# CH583SFR register map
Vendor: WCH Ltd.; Series: CH58x; File version: 1.0
CPU: RISC-V r0p0, little endian, no MPU, no FPU, 2 interrupt priority bits
Registers are 8-bit, read-write, reset 0x0 unless marked. A register's access mark holds for its fields unless they carry their own. Offsets are from the block's base; [hi:lo] are bit positions; {n}, {i} and the like mark numbered series.

## SYS — System Control Register
Base 0x40001000
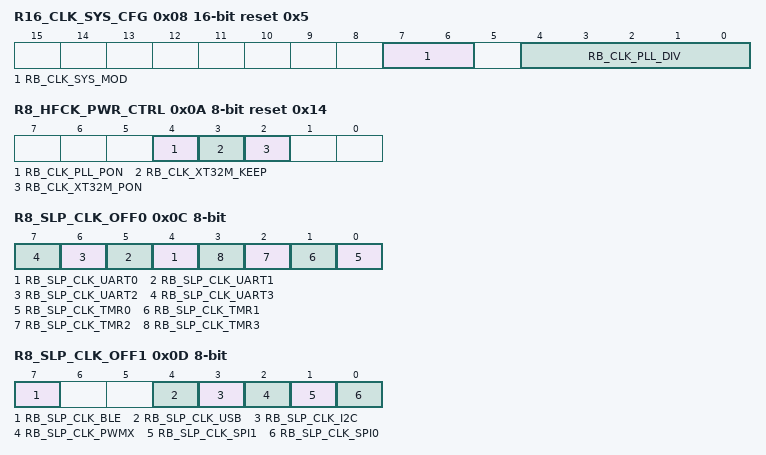
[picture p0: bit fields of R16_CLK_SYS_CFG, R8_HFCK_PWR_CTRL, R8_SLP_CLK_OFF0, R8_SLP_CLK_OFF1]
0x08 R16_CLK_SYS_CFG 16-bit reset 0x5 — RWA, system clock configuration, SAM
  [7:6] RB_CLK_SYS_MOD — RWA, system clock source mode: 00=divided from 32MHz, 01=divided from PLL-480MHz, 10=directly from 32MHz, 11=directly from 32KHz
  [4:0] RB_CLK_PLL_DIV — RWA, output clock divider from PLL or CK32M
0x0A R8_HFCK_PWR_CTRL reset 0x14 — RWA, high frequency clock module power control, SAM
  [4] RB_CLK_PLL_PON — RWA, PLL power control: 0=power down, 1-power on
  [3] RB_CLK_XT32M_KEEP — RWA, external 32MHz oscillator power keep under halt mode: 0=auto stop, 1=keep running
  [2] RB_CLK_XT32M_PON — RWA, external 32MHz oscillator power control: 0=power down, 1-power on
0x0C R8_SLP_CLK_OFF0 Read or  Write under safe Accessing mode — RWA, sleep clock off control byte 0, SAM
  [n+4] RB_SLP_CLK_UART{n} (n=0..3) — RWA, close UART{n} clock
  [n] RB_SLP_CLK_TMR{n} (n=0..3) — RWA, close TMR{n} clock
0x0D R8_SLP_CLK_OFF1 Read or  Write under safe Accessing mode — RWA, sleep clock off control byte 1, SAM
  [7] RB_SLP_CLK_BLE — RWA, close BLE clock
  [4] RB_SLP_CLK_USB — RWA, close USB clock
  [3] RB_SLP_CLK_I2C — RWA, close I2C clock
  [2] RB_SLP_CLK_PWMX — RWA, close PWMx clock
  [1] RB_SLP_CLK_SPI1 — RWA, close SPI1 clock
  [0] RB_SLP_CLK_SPI0 — RWA, close SPI0 clock
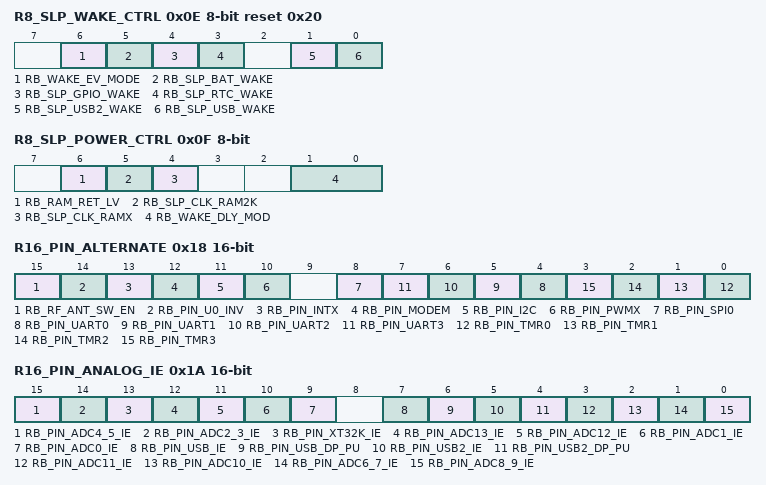
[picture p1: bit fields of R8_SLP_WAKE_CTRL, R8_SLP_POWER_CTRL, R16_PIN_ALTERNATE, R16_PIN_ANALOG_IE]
0x0E R8_SLP_WAKE_CTRL Read or Write under safe Accessing mode reset 0x20 — RWA, wake control, SAM
  [6] RB_WAKE_EV_MODE — RWA, event wakeup mode
  [5] RB_SLP_BAT_WAKE — RWA, enable BAT waking
  [4] RB_SLP_GPIO_WAKE — RWA, enable GPIO waking
  [3] RB_SLP_RTC_WAKE — RWA, enable RTC waking
  [1] RB_SLP_USB2_WAKE — RWA, enable USB2 waking
  [0] RB_SLP_USB_WAKE — RWA, enable USB waking
0x0F R8_SLP_POWER_CTRL Read or Write under safe Accessing mode — RWA, peripherals power down control, SAM
  [6] RB_RAM_RET_LV — RWA, SRAM retention voltage selection
  [5] RB_SLP_CLK_RAM2K — RWA, close retention 2KB SRAM clock
  [4] RB_SLP_CLK_RAMX — RWA, close main SRAM clock
  [1:0] RB_WAKE_DLY_MOD — RWA, wakeup delay time selection
0x18 R16_PIN_ALTERNATE 16-bit — RW, function pin alternate configuration
  [15] RB_RF_ANT_SW_EN — RW, RF antenna switch control output enable
  [14] RB_PIN_U0_INV — RW, SCL/SDA alternRW, RXD0/RXD0_/TXD0/TXD0_ invert input/output enableate pin enable
  [13] RB_PIN_INTX — RW, interrupt INT24/INT25 alternate pin enable
  [12] RB_PIN_MODEM — RW, DSR/DTR alternate pin enable
  [11] RB_PIN_I2C — RW, SCL/SDA alternate pin enable
  [10] RB_PIN_PWMX — RW, PWM4/PWM5/PWM7/PWM8/PWM9 alternate pin enable
  [8] RB_PIN_SPI0 — RW, SCS/SCK0/MOSI/MISO alternate pin enable
  [n+4] RB_PIN_UART{n} (n=0..3) — RW, RXD{n}/TXD{n} alternate pin enable
  [n] RB_PIN_TMR{n} (n=0..3) — RW, TMR{n} alternate pin enable
0x1A R16_PIN_ANALOG_IE 16-bit — RW, analog pin enable and digital input disable
  [15] RB_PIN_ADC4_5_IE — RW, ADC/TouchKey channel 4/5 digital input disable: 0=digital input enable, 1=digital input disable
  [14] RB_PIN_ADC2_3_IE — RW, ADC/TouchKey channel 2/3 digital input disable: 0=digital input enable, 1=digital input disable
  [13] RB_PIN_XT32K_IE — RW, external 32KHz oscillator digital input disable: 0=digital input enable, 1=digital input disable
  [12] RB_PIN_ADC13_IE — RW, ADC/TouchKey channel13 digital input disable: 0=digital input enable, 1=digital input disable
  [11] RB_PIN_ADC12_IE — RW, ADC/TouchKey channel12 digital input disable: 0=digital input enable, 1=digital input disable
  [10] RB_PIN_ADC1_IE — RW, ADC/TouchKey channel1 digital input disable: 0=digital input enable, 1=digital input disable
  [9] RB_PIN_ADC0_IE — RW, ADC/TouchKey channel0 digital input disable: 0=digital input enable, 1=digital input disable
  [7] RB_PIN_USB_IE — RW, USB analog I/O enable: 0=analog I/O disable, 1=analog I/O enable
  [6] RB_PIN_USB_DP_PU — RW,USB UDP internal pullup resistance enable
  [5] RB_PIN_USB2_IE — RW, USB analog I/O enable: 0=analog I/O disable, 1=analog I/O enable
  [4] RB_PIN_USB2_DP_PU — RW,USB2 UDP internal pullup resistance enable
  [3] RB_PIN_ADC11_IE — RW, ADC/TouchKey channel 11 digital input disable
  [2] RB_PIN_ADC10_IE — RW, ADC/TouchKey channel 10 digital input disable
  [1] RB_PIN_ADC6_7_IE — RW, ADC/TouchKey channel 7/6 digital input disable
  [0] RB_PIN_ADC8_9_IE — RW, ADC/TouchKey channel 9/8 digital input disable
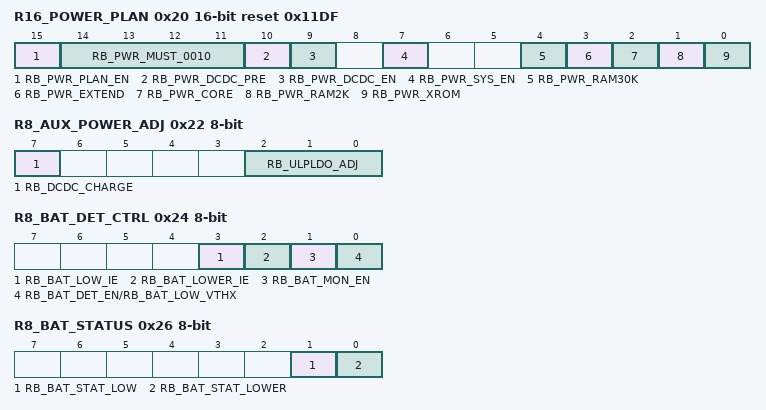
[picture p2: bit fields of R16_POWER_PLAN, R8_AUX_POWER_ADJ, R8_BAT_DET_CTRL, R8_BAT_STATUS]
0x20 R16_POWER_PLAN 16-bit Read or Write under safe Accessing mode reset 0x11DF — RWA, power plan before sleep instruction, SAM
  [15] RB_PWR_PLAN_EN ro — RWA, must write 0010
  [14:11] RB_PWR_MUST_0010 ro — RWA, power plan enable, auto clear after sleep executed
  [10] RB_PWR_DCDC_PRE — RWA, DC/DC converter pre-enable
  [9] RB_PWR_DCDC_EN — RWA, DC/DC converter enable: 0=DC/DC disable and bypass, 1=DC/DC enable
  [7] RB_PWR_SYS_EN — RWA, power for system
  [4] RB_PWR_RAM30K — RWA, power for main SRAM
  [3] RB_PWR_EXTEND — RWA, power retention for USB and BLE
  [2] RB_PWR_CORE — RWA, power retention for core and base peripherals
  [1] RB_PWR_RAM2K — RWA, power for retention 2KB SRAM
  [0] RB_PWR_XROM — RWA, power for retention 2KB SRAM
0x22 R8_AUX_POWER_ADJ Read or Write under safe Accessing mode — RWA, aux power adjust control, SAM
  [7] RB_DCDC_CHARGE rw — RWA, Ultra-Low-Power LDO voltage adjust
  [2:0] RB_ULPLDO_ADJ rw — RWA, Ultra-Low-Power LDO voltage adjust
0x24 R8_BAT_DET_CTRL Read / Write under safe Accessing mode — RWA, battery voltage detector control, SAM
  [3] RB_BAT_LOW_IE — RWA, interrupt enable for battery low voltage
  [2] RB_BAT_LOWER_IE — RWA, interrupt enable for battery lower voltage
  [1] RB_BAT_MON_EN — RWA, battery voltage monitor enable under sleep mode
  [0] RB_BAT_DET_EN/RB_BAT_LOW_VTHX — RWA, battery voltage detector enable/select monitor threshold voltage
0x25 R8_BAT_DET_CFG Read or Write under safe Accessing mode reset 0x1 — RWA, battery voltage detector configuration, SAM
  [1:0] RB_BAT_LOW_VTH — RWA, select threshold voltage of battery voltage low
0x26 R8_BAT_STATUS ro — RO, battery status
  [1] RB_BAT_STAT_LOW — RO, battery low voltage status, high action
  [0] RB_BAT_STAT_LOWER — RO, battery lower voltage status, high action
0x2C R16_INT32K_TUNE 16-bit Read or Write under safe Accessing mode reset 0x1011 — RWA, internal 32KHz oscillator tune control, SAM
  [12:0] RB_INT32K_TUNE — RWA, internal 32KHz oscillator frequency tune
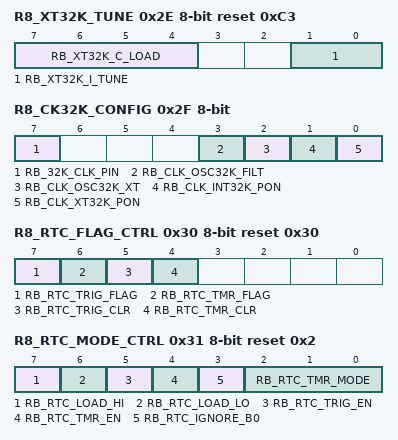
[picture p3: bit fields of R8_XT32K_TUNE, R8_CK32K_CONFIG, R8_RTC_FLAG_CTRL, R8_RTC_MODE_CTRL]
0x2E R8_XT32K_TUNE Read or Write under safe Accessing mode reset 0xC3 — RWA, external 32KHz oscillator tune control, SAM
  [7:4] RB_XT32K_C_LOAD — RWA, external 32KHz oscillator load capacitor tune: Cap = RB_XT32K_C_LOAD + 12pF
  [1:0] RB_XT32K_I_TUNE — RWA, external 32KHz oscillator current tune: 00=75% current, 01=standard current, 10=150% current, 11=200% current
0x2F R8_CK32K_CONFIG Read or  Write under safe Accessing mode reset not defined — RWA, 32KHz oscillator configure
  [7] RB_32K_CLK_PIN ro — RO, 32KHz oscillator clock pin status
  [3] RB_CLK_OSC32K_FILT rw — RWA, internal 32KHz oscillator low noise mode enable
  [2] RB_CLK_OSC32K_XT rw — RWA, 32KHz oscillator source selection: 0=RC, 1=XT
  [1] RB_CLK_INT32K_PON rw — RWA, internal 32KHz oscillator power on
  [0] RB_CLK_XT32K_PON rw — RWA, external 32KHz oscillator power on
0x30 R8_RTC_FLAG_CTRL reset 0x30 — RW, RTC flag and clear control
  [7] RB_RTC_TRIG_FLAG ro — RO, RTC trigger action flag
  [6] RB_RTC_TMR_FLAG ro — RO, RTC timer action flag
  [5] RB_RTC_TRIG_CLR — RW, set 1 to clear RTC trigger action flag, auto clear
  [4] RB_RTC_TMR_CLR — RW, set 1 to clear RTC timer action flag, auto clear
0x31 R8_RTC_MODE_CTRL Read or Write under safe Accessing mode reset 0x2 — RWA, RTC mode control, SAM
  [7] RB_RTC_LOAD_HI — RWA, set 1 to load RTC count high word R32_RTC_CNT_DAY, auto clear after loaded
  [6] RB_RTC_LOAD_LO — RWA, set 1 to load RTC count low word R32_RTC_CNT_32K, auto clear after loaded
  [5] RB_RTC_TRIG_EN — RWA, RTC trigger mode enable
  [4] RB_RTC_TMR_EN — RWA, RTC timer mode enable
  [3] RB_RTC_IGNORE_B0 — RWA, force ignore bit0 for trigger mode: 0=compare bit0, 1=ignore bit0
  [2:0] RB_RTC_TMR_MODE — RWA, RTC timer mode: 000=0.125S, 001=0.25S, 010=0.5S, 011=1S, 100=2S, 101=4S, 110=8S, 111=16S
0x34 R32_RTC_TRIG 32-bit Read or Write under safe Accessing mode — RWA, RTC trigger value, SAM
  [31:0] R32_RTC_TRIG — RWA, RTC trigger value
0x38 R16_RTC_CNT_32K 16-bit ro — RO, RTC count based 32KHz
  [15:0] R16_RTC_CNT_32K — RWA,RTC count based 32KHz
0x3A R16_RTC_CNT_2S 16-bit ro — RO, RTC count based 2 second
0x3C R32_RTC_CNT_DAY 32-bit ro — RO, RTC count based one day, only low 14 bit
  [13:0] R32_RTC_CNT_DAY — RWA,RTC count based one day
0x40 R8_SAFE_ACCESS_SIG read/write — WO, safe accessing sign register, must write SAFE_ACCESS_SIG1 then SAFE_ACCESS_SIG2 to enter safe accessing mode
  [6:4] RB_SAFE_ACC_TIMER — RO, safe accessing timer bit mask (16*clock number)
  [3] RB_SAFE_ACC_ACT — RO, indicate safe accessing status now: 0=locked, read only, 1=safe/unlocked (SAM), write enabled
  [1:0] RB_SAFE_ACC_MODE — RO, current safe accessing mode: 11=safe unlocked (SAM), other=locked (00..01..10..11)
  [7:0] R8_SAFE_ACCESS_SIG — WO, safe accessing sign register, must write 0x57 then 0xA8 to enter safe accessing mode
0x41 R8_CHIP_ID -Read only for Fixed value reset 0x83 — RF, chip ID register, always is ID_CH58*
  [7:0] R8_CHIP_ID — RF,chip ID register
0x42 R8_SAFE_ACCESS_ID -Read only for Fixed value reset 0xC — RF, safe accessing ID register, always 0x0C
  [7:0] R8_SAFE_ACCESS_ID — RF,safe accessing ID register
0x43 R8_WDOG_COUNT — RW, watch-dog count, count by clock frequency Fsys/131072
  [7:0] R8_WDOG_COUNT — RF,watch-dog count, count by clock frequency Fsys/131072
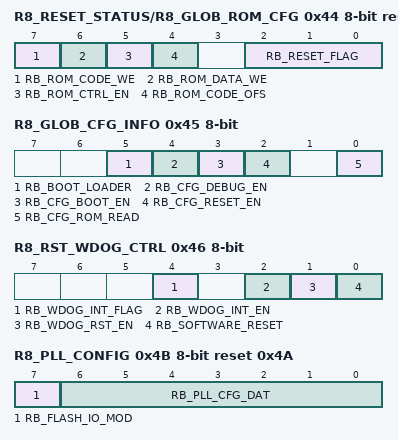
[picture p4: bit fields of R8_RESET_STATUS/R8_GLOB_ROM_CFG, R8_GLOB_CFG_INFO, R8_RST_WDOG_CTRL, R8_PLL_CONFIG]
0x44 R8_RESET_STATUS/R8_GLOB_ROM_CFG -Read only for Fixed value reset 0x1 — RWA, reset status, SAM or flash ROM configuration
  [7] RB_ROM_CODE_WE rw — RWA, enable flash ROM code area being erase or write
  [6] RB_ROM_DATA_WE rw — RWA,enable flash ROM data and code area being erase/write
  [5] RB_ROM_CTRL_EN rw — RWA, enable flash ROM control interface enable
  [4] RB_ROM_CODE_OFS rw — RWA, code offset address selection in Flash ROM: 0=start address 0x000000, 1=start address 0x008000
  [2:0] RB_RESET_FLAG ro — RO, recent reset flag
0x45 R8_GLOB_CFG_INFO ro reset not defined — RO, global configuration information and status
  [5] RB_BOOT_LOADER — RO, indicate boot loader status: 0=application status (by software reset), 1=boot loader status
  [4] RB_CFG_DEBUG_EN — RO, debug enable status
  [3] RB_CFG_BOOT_EN — RO, boot-loader enable status
  [2] RB_CFG_RESET_EN — RO, manual reset input enable status
  [0] RB_CFG_ROM_READ — RO, indicate protected status of Flash ROM code and data: 0=reading protect, 1=enable read by external programmer
0x46 R8_RST_WDOG_CTRL Read or Write under safe Accessing mode — RWA, reset and watch-dog control, SAM
  [4] RB_WDOG_INT_FLAG — RW1, watch-dog timer overflow interrupt flag, cleared by RW1 or reload watch-dog count or __SEV(Send-Event)
  [2] RB_WDOG_INT_EN — RWA, watch-dog timer overflow interrupt enable: 0=disable, 1=enable
  [1] RB_WDOG_RST_EN — RWA, enable watch-dog reset if watch-dog timer overflow: 0=as timer only, 1=enable reset if timer overflow
  [0] RB_SOFTWARE_RESET — WA or WZ, global software reset, high action, auto clear
0x47 R8_GLOB_RESET_KEEP — RW, value keeper during global reset
0x4B R8_PLL_CONFIG Read or Write under safe Accessing mode reset 0x4A — RWA, PLL configuration control, SAM
  [7] RB_FLASH_IO_MOD rw — RWA, flash ROM interface mode
  [6:0] RB_PLL_CFG_DAT rw — RWA, PLL configure data
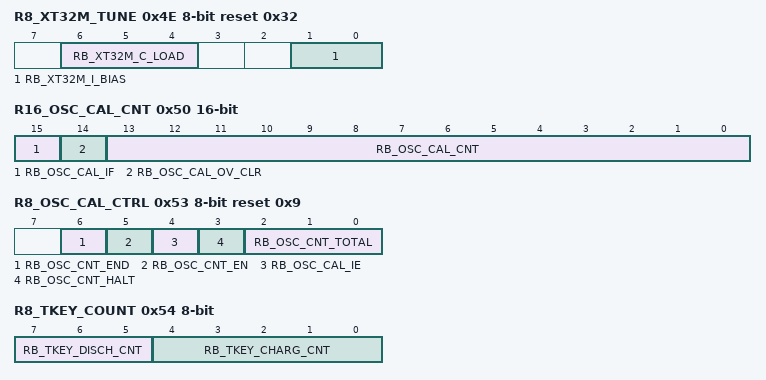
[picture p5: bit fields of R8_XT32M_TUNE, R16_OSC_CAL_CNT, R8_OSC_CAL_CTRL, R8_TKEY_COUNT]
0x4E R8_XT32M_TUNE Read or Write under safe Accessing mode reset 0x32 — RWA, external 32MHz oscillator tune control, SAM
  [6:4] RB_XT32M_C_LOAD rw — RWA, external 32MHz oscillator load capacitor tune: Cap = RB_XT32M_C_LOAD * 2 + 10pF
  [1:0] RB_XT32M_I_BIAS rw — RWA, external 32MHz oscillator bias current tune: 00=75% current, 01=standard current, 10=125% current, 11=150% current
0x50 R16_OSC_CAL_CNT 16-bit ro — RO, system clock count value for 32KHz multi-cycles
  [15] RB_OSC_CAL_IF — RW1, interrupt flag for oscillator capture end, set 1 to clear
  [14] RB_OSC_CAL_OV_CLR — RW1, indicate R8_OSC_CAL_OV_CNT not zero, set 1 to clear R8_OSC_CAL_OV_CNT
  [13:0] RB_OSC_CAL_CNT — RO, system clock count value for 32KHz multi-cycles
0x52 R8_OSC_CAL_OV_CNT Read Only — RO, oscillator frequency calibration overflow times
  [7:0] R8_OSC_CAL_OV_CNT read only
0x53 R8_OSC_CAL_CTRL Read or Write under safe Accessing mode reset 0x9 — RWA, oscillator frequency calibration control, SAM
  [6] RB_OSC_CNT_END rw — RWA, select oscillator capture end mode: 0=normal, 1=append 2 cycles
  [5] RB_OSC_CNT_EN rw — RWA, calibration counter enable
  [4] RB_OSC_CAL_IE rw — RWA, interrupt enable for oscillator capture end
  [3] RB_OSC_CNT_HALT ro — RO, calibration counter halt status: 0=counting, 1=halt for reading count value
  [2:0] RB_OSC_CNT_TOTAL rw — RWA, total cycles mode for oscillator capture
0x54 R8_TKEY_COUNT — RW, Touchkey charge and discharge count
  [7:5] RB_TKEY_DISCH_CNT — RW, Touchkey discharge count
  [4:0] RB_TKEY_CHARG_CNT — RW, Touchkey charge count
0x56 R8_TKEY_CONVERT — RW, Touchkey convert start control
  [0] RB_TKEY_START
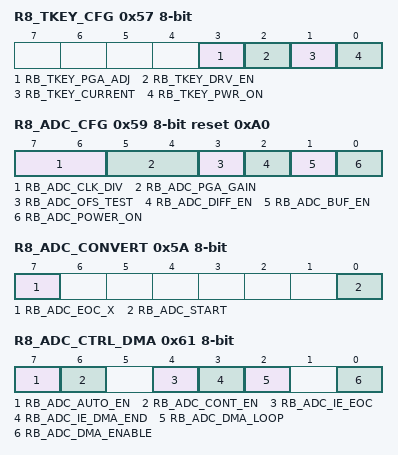
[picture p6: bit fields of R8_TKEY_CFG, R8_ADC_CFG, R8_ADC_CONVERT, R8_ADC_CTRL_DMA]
0x57 R8_TKEY_CFG — RW, Touchkey configure
  [3] RB_TKEY_PGA_ADJ — RW, ADC input PGA speed selection
  [2] RB_TKEY_DRV_EN — RW, Touchkey drive shield enable
  [1] RB_TKEY_CURRENT — RW, Touchkey charge current selection
  [0] RB_TKEY_PWR_ON — RW, Touchkey power on
0x58 R8_ADC_CHANNEL reset 0xF — RW, ADC input channel selection
  [3:0] RB_ADC_CH_INX — RW, ADC input channel index
0x59 R8_ADC_CFG reset 0xA0 — RW, ADC configure
  [7:6] RB_ADC_CLK_DIV — RW, select ADC clock frequency: 00=3.2MHz, 01=2.67MHz, 10=5.33MHz, 11=4MHz
  [5:4] RB_ADC_PGA_GAIN — RW, set ADC input PGA gain: 00=-12dB, 01=-6dB, 10=0dB, 11=6dB
  [3] RB_ADC_OFS_TEST — RW, enable ADC offset test mode: 0=normal mode, 1=short to test offset
  [2] RB_ADC_DIFF_EN — RW, ADC input channel mode: 0=single-end, 1=differnetial
  [1] RB_ADC_BUF_EN — RW, ADC input buffer enable
  [0] RB_ADC_POWER_ON — RW, ADC power control: 0=power down, 1=power on
0x5A R8_ADC_CONVERT — RW, ADC convert control
  [7] RB_ADC_EOC_X ro — RO, end of ADC conversion flag
  [0] RB_ADC_START — RW, ADC convert start control: 0=stop ADC convert, 1=start an ADC convert, auto clear
0x5B R8_TEM_SENSOR — RW, temperature sensor control
  [7] RB_TEM_SEN_PWR_ON — RW, temperature sensor power control: 0=power down, 1=power on
0x5C R16_ADC_DATA 16-bit ro — RO, ADC data
  [11:0] RB_ADC_DATA — RO, ADC conversion data
0x5E R8_ADC_INT_FLAG ro — RO, ADC interrupt flag register
  [7] RB_ADC_IF_EOC — RO, ADC conversion interrupt flag: 0=free or converting, 1=end of conversion, interrupt action, write R8_ADC_CONVERT to clear flag
0x60 R32_ADC_DMA_CTRL write-read — RO, ADC DMA control and status register
  [7:0] R32_ADC_DMA_CTRL — RW, ADC DMA enable
0x61 R8_ADC_CTRL_DMA write-read — RW, ADC DMA control
  [7] RB_ADC_AUTO_EN — RW, enable auto continuing ADC for DMA
  [6] RB_ADC_CONT_EN — RW, enable contineous conversion ADC
  [4] RB_ADC_IE_EOC — RW, enable interrupt for end of ADC conversion
  [3] RB_ADC_IE_DMA_END — RW, enable interrupt for ADC DMA completion
  [2] RB_ADC_DMA_LOOP — RW, ADC DMA address loop enable
  [0] RB_ADC_DMA_ENABLE — RW, ADC DMA enable
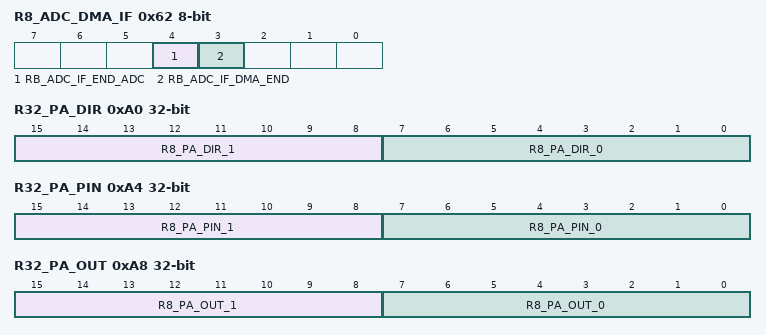
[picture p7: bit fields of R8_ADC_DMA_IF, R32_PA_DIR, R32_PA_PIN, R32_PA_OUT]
0x62 R8_ADC_DMA_IF write-read — RO, ADC interrupt flag
  [4] RB_ADC_IF_END_ADC — interrupt flag for end of ADC conversion
  [3] RB_ADC_IF_DMA_END — interrupt flag for ADC DMA completion
0x63 R8_ADC_AUTO_CYCLE write-read — RO, ADC interrupt flag
  [7:0] R8_ADC_AUTO_CYCLE — auto ADC cycle value, unit is 16 Fsys
0x64 R16_ADC_DMA_NOW ro — RO, ADC DMA current address
  [15:0] R16_ADC_DMA_NOW — ADC DMA current address
0x68 R16_ADC_DMA_BEG write-read — RW, ADC DMA begin address
  [15:0] R16_ADC_DMA_BEG — ADC DMA begin address
0x6C R16_ADC_DMA_END write-read — RW, ADC DMA end address
  [15:0] R16_ADC_DMA_END — ADC DMA end address
0x90 R16_PA_INT_EN 16-bit — RW, GPIO PA interrupt enable
  [15:0] R16_PA_INT_EN — GPIO PA interrupt enable
0x92 R16_PB_INT_EN 16-bit — RW, GPIO PB interrupt enable
  [15:0] R16_PB_INT_EN — GPIO PB interrupt enable
0x94 R16_PA_INT_MODE 16-bit — RW, GPIO PA interrupt mode: 0=level action, 1=edge action
  [15:0] R16_PA_INT_MODE — GPIO PA interrupt mode
0x96 R16_PB_INT_MODE 16-bit — RW, GPIO PB interrupt mode: 0=level action, 1=edge action;RW, status for parallel slave read
  [15:0] R16_PB_INT_MODE — GPIO PB interrupt mode
0x9C R16_PA_INT_IF 16-bit — RW1, GPIO PA interrupt flag
  [15:0] R16_PA_INT_IF — GPIO PA interrupt flag
0x9E R16_PB_INT_IF 16-bit — RW1, GPIO PB interrupt flag
  [15:0] R16_PB_INT_IF — GPIO PB interrupt flag
0xA0 R32_PA_DIR 32-bit — RW, GPIO PA I/O direction: 0=in, 1=out
  [15:8] R8_PA_DIR_1 — GPIO PA I/O direction byte 1
  [7:0] R8_PA_DIR_0 — GPIO PA I/O direction byte 0
0xA4 R32_PA_PIN 32-bit ro — RO, GPIO PA input
  [15:8] R8_PA_PIN_1 — GPIO PA input byte 1
  [7:0] R8_PA_PIN_0 — GPIO PA input byte 0
0xA8 R32_PA_OUT 32-bit — RW, GPIO PA output
  [15:8] R8_PA_OUT_1 — GPIO PA output byte 1
  [7:0] R8_PA_OUT_0 — GPIO PA output byte 0
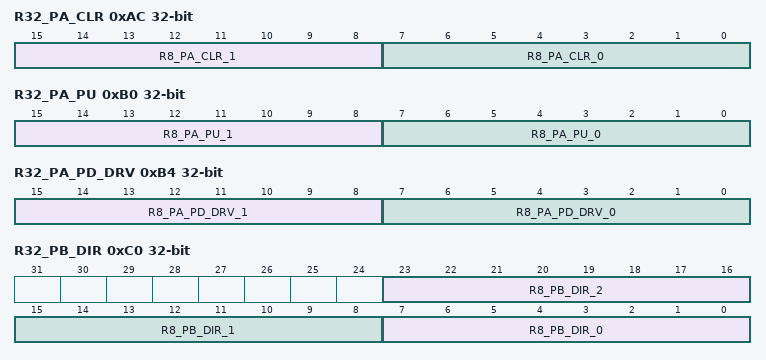
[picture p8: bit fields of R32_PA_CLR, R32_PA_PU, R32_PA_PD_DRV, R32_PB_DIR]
0xAC R32_PA_CLR 32-bit — WZ, GPIO PA clear output: 0=keep, 1=clear
  [15:8] R8_PA_CLR_1 — GPIO PA clear output byte 1
  [7:0] R8_PA_CLR_0 — GPIO PA clear output byte 0
0xB0 R32_PA_PU 32-bit — RW, GPIO PA pullup resistance enable
  [15:8] R8_PA_PU_1 — GPIO PA pullup resistance enable byte 0
  [7:0] R8_PA_PU_0 — GPIO PA pullup resistance enable byte 0
0xB4 R32_PA_PD_DRV 32-bit — RW, PA pulldown for input or PA driving capability for output
  [15:8] R8_PA_PD_DRV_1 — PA pulldown for input or PA driving capability for output byte 1
  [7:0] R8_PA_PD_DRV_0 — PA pulldown for input or PA driving capability for output byte 0
0xC0 R32_PB_DIR 32-bit — RW, GPIO PB I/O direction: 0=in, 1=out
  [23:16] R8_PB_DIR_2 — GPIO PB I/O direction byte 2
  [15:8] R8_PB_DIR_1 — GPIO PB I/O direction byte 1
  [7:0] R8_PB_DIR_0 — GPIO PB I/O direction byte 0
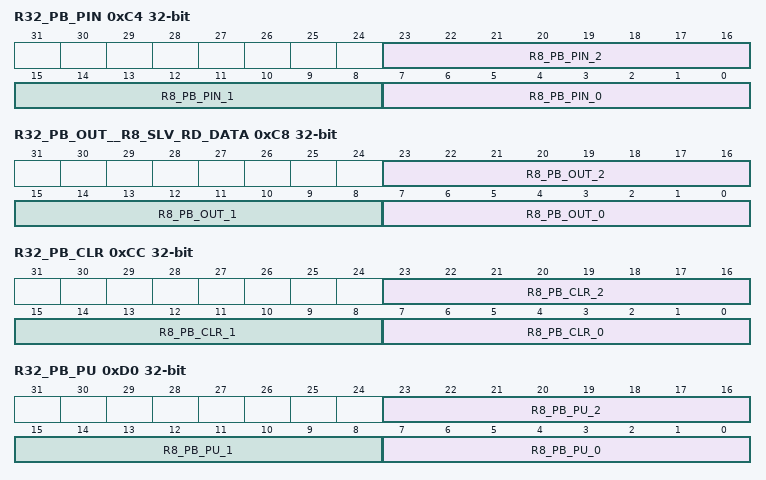
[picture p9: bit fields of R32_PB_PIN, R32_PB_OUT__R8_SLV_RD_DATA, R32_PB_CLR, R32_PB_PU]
0xC4 R32_PB_PIN 32-bit ro — RO, GPIO PB input
  [23:16] R8_PB_PIN_2 — GPIO PB input byte 2
  [15:8] R8_PB_PIN_1 — GPIO PB input byte 1
  [7:0] R8_PB_PIN_0 — GPIO PB input byte 0
0xC8 R32_PB_OUT__R8_SLV_RD_DATA 32-bit — RW, GPIO PB output;RW, data for parallel slave read
  [23:16] R8_PB_OUT_2 — GPIO PB output byte 2
  [15:8] R8_PB_OUT_1 — GPIO PB output byte 1
  [7:0] R8_PB_OUT_0 — GPIO PB output byte 0
0xCC R32_PB_CLR 32-bit — WZ, GPIO PB clear output: 0=keep, 1=clear
  [23:16] R8_PB_CLR_2 — GPIO PB clear output byte 2
  [15:8] R8_PB_CLR_1 — GPIO PB clear output byte 1
  [7:0] R8_PB_CLR_0 — GPIO PB clear output byte 0
0xD0 R32_PB_PU 32-bit — RW, GPIO PB pullup resistance enable
  [23:16] R8_PB_PU_2 — GPIO PB pullup resistance enable byte 2
  [15:8] R8_PB_PU_1 — GPIO PB pullup resistance enable byte 1
  [7:0] R8_PB_PU_0 — GPIO PB pullup resistance enable byte 0
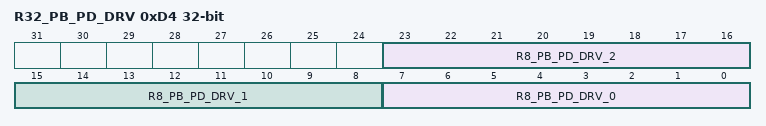
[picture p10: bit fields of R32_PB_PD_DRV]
0xD4 R32_PB_PD_DRV 32-bit — RW, PB pulldown for input or PB driving capability for output
  [23:16] R8_PB_PD_DRV_2 — PB pulldown for input or PB driving capability for output byte 0
  [15:8] R8_PB_PD_DRV_1 — PB pulldown for input or PB driving capability for output byte 0
  [7:0] R8_PB_PD_DRV_0 — PB pulldown for input or PB driving capability for output byte 0
